# GD32F3x0 register map
File version: 1.0
CPU: CM4 r2p1, little endian, no MPU, no FPU, 4 interrupt priority bits
Registers are 32-bit, read-write, reset 0x0 unless marked. A register's access mark holds for its fields unless they carry their own. Offsets are from the block's base; [hi:lo] are bit positions.

## CTC — Clock trim controller
Base 0x4000C800
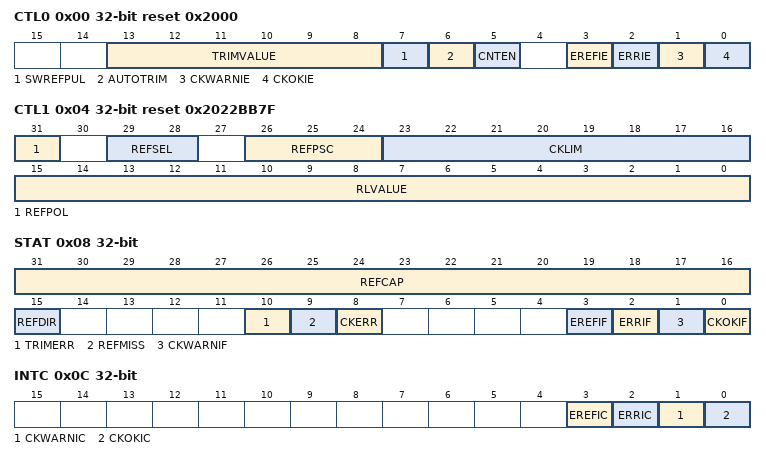
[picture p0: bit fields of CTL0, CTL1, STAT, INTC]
0x00 CTL0 reset 0x2000 — Control Register 0
  [13:8] TRIMVALUE — IRC48M trim value
  [7] SWREFPUL — Software reference source sync pulse
  [6] AUTOTRIM — Hardware automatically trim mode
  [5] CNTEN — CTC counter enable
  [3] EREFIE — EREFIF interrupt enable
  [2] ERRIE — Error (ERRIF) interrupt enable
  [1] CKWARNIE — Clock trim warning (CKWARNIF) interrupt enable
  [0] CKOKIE — Clock trim OK (CKOKIF) interrupt enable
0x04 CTL1 reset 0x2022BB7F — Control Register 1
  [31] REFPOL — Reference signal source polarity
  [29:28] REFSEL — Reference signal source selection
  [26:24] REFPSC — Reference signal source prescaler
  [23:16] CKLIM — Clock trim base limit value
  [15:0] RLVALUE — CTC counter reload value
0x08 STAT ro — Status Register
  [31:16] REFCAP — CTC counter capture when reference sync pulse
  [15] REFDIR — CTC trim counter direction when reference sync pulse
  [10] TRIMERR — Trim value error bit
  [9] REFMISS — Reference sync pulse miss
  [8] CKERR — Clock trim error bit
  [3] EREFIF — Expect reference interrupt flag
  [2] ERRIF — Error interrupt flag
  [1] CKWARNIF — Clock trim warning interrupt flag
  [0] CKOKIF — Clock trim OK interrupt flag
0x0C INTC wo — Interrupt clear Register
  [3] EREFIC — EREFIF interrupt clear bit
  [2] ERRIC — ERRIF interrupt clear bit
  [1] CKWARNIC — CKWARNIF interrupt clear bit
  [0] CKOKIC — CKOKIF interrupt clear bit

## I2C0 — Inter integrated circuit
Base 0x40005400
Same registers: I2C1 0x40005800
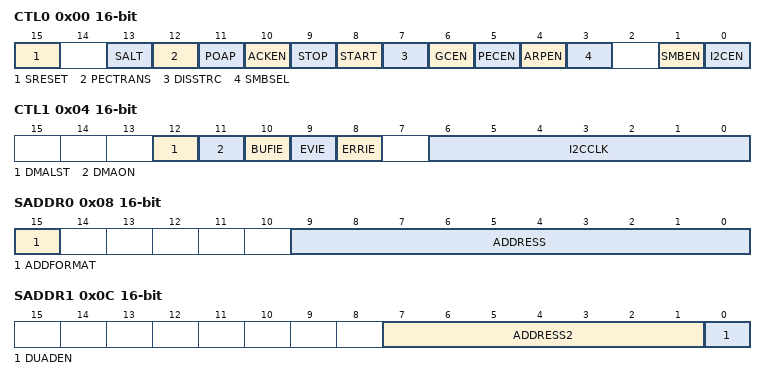
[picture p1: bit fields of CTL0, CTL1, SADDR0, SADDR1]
0x00 CTL0 16-bit — Control register 0
  [15] SRESET — Software reset
  [13] SALT — SMBus alert
  [12] PECTRANS — Packet error checking
  [11] POAP — Acknowledge/PEC Position (for data reception)
  [10] ACKEN — Acknowledge enable
  [9] STOP — Stop condition
  [8] START — Start generation
  [7] DISSTRC — Clock stretching disable (Slave mode)
  [6] GCEN — General call enable
  [5] PECEN — PEC enable
  [4] ARPEN — ARP enable
  [3] SMBSEL — SMBus type
  [1] SMBEN — SMBus mode
  [0] I2CEN — Peripheral enable
0x04 CTL1 16-bit — Control register 1
  [12] DMALST — Flag indicating DMA last transfer
  [11] DMAON — DMA mode switch
  [10] BUFIE — Buffer interrupt enable
  [9] EVIE — Event interrupt enable
  [8] ERRIE — Error interrupt enable
  [6:0] I2CCLK — Peripheral clock frequency
0x08 SADDR0 16-bit — Own address register 0
  [15] ADDFORMAT — Addressing mode (slave mode)
  [9:0] ADDRESS — Interface address
0x0C SADDR1 16-bit — Own address register 1
  [7:1] ADDRESS2 — Interface address
  [0] DUADEN — Dual addressing mode enable
0x10 DATA 16-bit
  [7:0] TRB — Transmission or reception data buffer
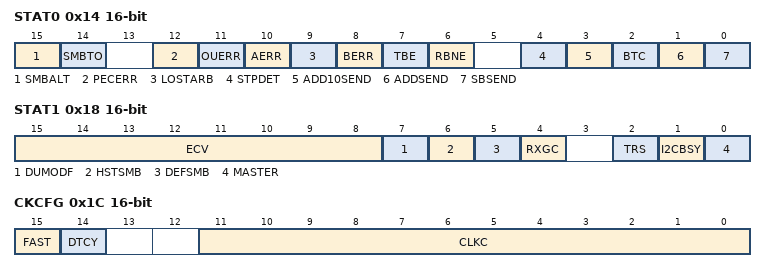
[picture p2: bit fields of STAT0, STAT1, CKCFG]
0x14 STAT0 16-bit access per field — Transfer status register 0
  [15] SMBALT rw — SMBus alert
  [14] SMBTO rw — Timeout signal in SMBus mode
  [12] PECERR rw — PEC error when receiving data
  [11] OUERR rw — Overrun/Underrun occurs in slave mode
  [10] AERR rw — Acknowledge error
  [9] LOSTARB rw — Arbitration lost (master mode)
  [8] BERR rw — Bus error
  [7] TBE ro — I2C_DATA is Empty during transmitting
  [6] RBNE ro — I2C_DATA is not Empty during receiving
  [4] STPDET ro — Stop detection (slave mode)
  [3] ADD10SEND ro — Header of 10-bit address is sent in master mode
  [2] BTC ro — Byte transmission completed
  [1] ADDSEND ro — Address sent (master mode)/matched (slave mode)
  [0] SBSEND ro — Start bit (Master mode)
0x18 STAT1 16-bit ro — Transfer status register 1
  [15:8] ECV — Packet error checking register
  [7] DUMODF — Dual flag (Slave mode)
  [6] HSTSMB — SMBus host header (Slave mode)
  [5] DEFSMB — SMBus device default address (Slave mode)
  [4] RXGC — General call address (Slave mode)
  [2] TRS — Transmitter/receiver
  [1] I2CBSY — Bus busy
  [0] MASTER — Master/slave
0x1C CKCFG 16-bit — Clock configure register
  [15] FAST — I2C master mode selection
  [14] DTCY — Fast mode duty cycle
  [11:0] CLKC — Clock control register in Fast/Standard mode (Master mode)
0x20 RT 16-bit reset 0x2 — Rise time register
  [5:0] RISETIME — Maximum rise time in master mode
0x90 FMPCFG 16-bit — Fast-mode-plus configure register
  [0] FMPEN — Fast-mode-plus enable
